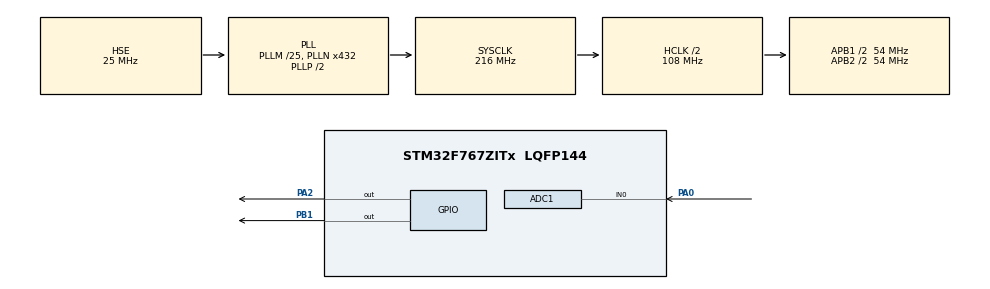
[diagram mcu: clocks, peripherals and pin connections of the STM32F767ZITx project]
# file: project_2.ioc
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ADC1.Channel-0\#ChannelRegularConversion=ADC_CHANNEL_0
ADC1.ClockPrescaler=ADC_CLOCK_SYNC_PCLK_DIV4
ADC1.ContinuousConvMode=ENABLE
ADC1.DMAContinuousRequests=ENABLE
ADC1.NbrOfConversion=1
ADC1.NbrOfConversionFlag=1
ADC1.Rank-0\#ChannelRegularConversion=1
ADC1.SamplingTime-0\#ChannelRegularConversion=ADC_SAMPLETIME_3CYCLES
ADC1.master=1
CORTEX_M7.default_mode_Activation=1
Dma.ADC1.0.Direction=DMA_PERIPH_TO_MEMORY
Dma.ADC1.0.FIFOMode=DMA_FIFOMODE_DISABLE
Dma.ADC1.0.Instance=DMA2_Stream0
Dma.ADC1.0.MemDataAlignment=DMA_MDATAALIGN_HALFWORD
Dma.ADC1.0.MemInc=DMA_MINC_ENABLE
Dma.ADC1.0.Mode=DMA_NORMAL
Dma.ADC1.0.PeriphDataAlignment=DMA_PDATAALIGN_HALFWORD
Dma.ADC1.0.PeriphInc=DMA_PINC_DISABLE
Dma.ADC1.0.Priority=DMA_PRIORITY_LOW
Dma.Request0=ADC1
Mcu.Family=STM32F7
Mcu.Name=STM32F767ZITx
Mcu.Package=LQFP144
NVIC.DMA2_Stream0_IRQn=true\:0\:0\:false\:false\:true\:false\:true\:true
NVIC.PriorityGroup=NVIC_PRIORITYGROUP_4
PA0/WKUP.Signal=ADCx_IN0
PA2.Signal=GPIO_Output
PB1.Signal=GPIO_Output
PD8.Signal=USART3_TX
PD9.Signal=USART3_RX
PH0/OSC_IN.Mode=HSE-External-Oscillator
PH0/OSC_IN.Signal=RCC_OSC_IN
PH1/OSC_OUT.Mode=HSE-External-Oscillator
PH1/OSC_OUT.Signal=RCC_OSC_OUT
ProjectManager.HeapSize=0x200
ProjectManager.StackSize=0x400
ProjectManager.TargetToolchain=STM32CubeIDE
RCC.AHBCLKDivider=RCC_SYSCLK_DIV2
RCC.AHBFreq_Value=108000000
RCC.APB1CLKDivider=RCC_HCLK_DIV2
RCC.APB1Freq_Value=54000000
RCC.APB1TimFreq_Value=108000000
RCC.APB2CLKDivider=RCC_HCLK_DIV2
RCC.APB2Freq_Value=54000000
RCC.APB2TimFreq_Value=108000000
RCC.CortexFreq_Value=108000000
RCC.HCLKFreq_Value=108000000
RCC.HSE_VALUE=25000000
RCC.HSI_VALUE=16000000
RCC.LSE_VALUE=32768
RCC.PLLM=25
RCC.PLLN=432
RCC.PLLSourceVirtual=RCC_PLLSOURCE_HSE
RCC.SYSCLKFreq_VALUE=216000000
RCC.SYSCLKSource=RCC_SYSCLKSOURCE_PLLCLK
RCC.USBFreq_Value=216000000
RCC.VCOOutputFreq_Value=432000000
SH.ADCx_IN0.0=ADC1_IN0,IN0
board=custom

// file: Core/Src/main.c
/* USER CODE BEGIN Header */
/**
  ******************************************************************************
  * @file           : main.c
  * @brief          : Main program body
  ******************************************************************************
  * @attention
  *
  * Copyright (c) 2026 STMicroelectronics.
  * All rights reserved.
  *
  * This software is licensed under terms that can be found in the LICENSE file
  * in the root directory of this software component.
  * If no LICENSE file comes with this software, it is provided AS-IS.
  *
  ******************************************************************************
  */
/* USER CODE END Header */
#include "main.h"
#include "adc.h"
#include "dma.h"
#include "gpio.h"

/* USER CODE BEGIN PD */
#define MAX_SAMPLES 1000
/* USER CODE END PD */

/* USER CODE BEGIN PV */
ALIGN_32BYTES(uint16_t adc_buffer[MAX_SAMPLES]);
volatile uint8_t adc_conv_complete = 0;
volatile uint32_t sampling_time_us = 0;
volatile uint16_t plot_val = 0; // ตัวแปรสำหรับส่งให้ SWV Trace
/* USER CODE END PV */

void SystemClock_Config(void);
static void MPU_Config(void);
/* USER CODE BEGIN PFP */
void Capture_ADC_DMA(void);
static inline uint32_t DWT_GetMicros(void);
/* USER CODE END PFP */

/* USER CODE BEGIN 0 */
static inline uint32_t DWT_GetMicros(void) {
    // ใช้ HAL_RCC_GetHCLKFreq() แทน SystemCoreClock เพื่อความแม่นยำ
    return DWT->CYCCNT / (HAL_RCC_GetHCLKFreq() / 1000000UL);
}

void HAL_ADC_ConvCpltCallback(ADC_HandleTypeDef* hadc) {
    if (hadc->Instance == ADC1) {
        adc_conv_complete = 1;
    }
}

void Capture_ADC_DMA(void) {
    adc_conv_complete = 0;

    uint32_t t_start = DWT_GetMicros();
    HAL_ADC_Start_DMA(&hadc1, (uint32_t*)adc_buffer, MAX_SAMPLES);

    // รอดูดข้อมูลจนครบ 1,000 จุด
    while (!adc_conv_complete);

    HAL_ADC_Stop_DMA(&hadc1);
    sampling_time_us = DWT_GetMicros() - t_start;

    // เคลียร์ D-Cache เพื่อให้ CPU อ่านค่าจริงจาก SRAM
    SCB_InvalidateDCache_by_Addr((uint32_t*)adc_buffer, sizeof(adc_buffer));
}
/* USER CODE END 0 */

int main(void)
{

  /* MPU Configuration--------------------------------------------------------*/
  MPU_Config();

  /* MCU Configuration--------------------------------------------------------*/

  /* Reset of all peripherals, Initializes the Flash interface and the Systick. */
  HAL_Init();

  /* Configure the system clock */
  SystemClock_Config();

  /* Initialize all configured peripherals */
  MX_GPIO_Init();
  MX_DMA_Init();
  MX_ADC1_Init();
  /* USER CODE BEGIN 2 */
  // เปิด Core Debug
  CoreDebug->DEMCR |= CoreDebug_DEMCR_TRCENA_Msk;

  // ปลดล็อก Software Lock ของ DWT บน Cortex-M7 (สำคัญมาก)
  *((volatile uint32_t *)0xE0001FB0) = 0xC5ACCE55;

  // รีเซ็ตตัวนับและเปิดการทำงานของ CYCCNT
  DWT->CYCCNT = 0;
  DWT->CTRL |= DWT_CTRL_CYCCNTENA_Msk;
  /* USER CODE END 2 */

  /* Infinite loop */
  /* USER CODE BEGIN WHILE */
  while (1)
  {
      Capture_ADC_DMA();
      for (int i = 0; i < MAX_SAMPLES; i++) {
              plot_val = adc_buffer[i];
          }
      HAL_Delay(10);
    /* USER CODE END WHILE */

  }
}

void SystemClock_Config(void)
{
  RCC_OscInitTypeDef RCC_OscInitStruct = {0};
  RCC_ClkInitTypeDef RCC_ClkInitStruct = {0};

  /** Configure the main internal regulator output voltage
  */
  __HAL_RCC_PWR_CLK_ENABLE();
  __HAL_PWR_VOLTAGESCALING_CONFIG(PWR_REGULATOR_VOLTAGE_SCALE3);

  /** Initializes the RCC Oscillators according to the specified parameters
  * in the RCC_OscInitTypeDef structure.
  */
  RCC_OscInitStruct.OscillatorType = RCC_OSCILLATORTYPE_HSE;
  RCC_OscInitStruct.HSEState = RCC_HSE_ON;
  RCC_OscInitStruct.PLL.PLLState = RCC_PLL_ON;
  RCC_OscInitStruct.PLL.PLLSource = RCC_PLLSOURCE_HSE;
  RCC_OscInitStruct.PLL.PLLM = 25;
  RCC_OscInitStruct.PLL.PLLN = 432;
  RCC_OscInitStruct.PLL.PLLP = RCC_PLLP_DIV2;
  RCC_OscInitStruct.PLL.PLLQ = 2;
  RCC_OscInitStruct.PLL.PLLR = 2;
  if (HAL_RCC_OscConfig(&RCC_OscInitStruct) != HAL_OK)
  {
    Error_Handler();
  }

  /** Activate the Over-Drive mode
  */
  if (HAL_PWREx_EnableOverDrive() != HAL_OK)
  {
    Error_Handler();
  }

  /** Initializes the CPU, AHB and APB buses clocks
  */
  RCC_ClkInitStruct.ClockType = RCC_CLOCKTYPE_HCLK|RCC_CLOCKTYPE_SYSCLK
                              |RCC_CLOCKTYPE_PCLK1|RCC_CLOCKTYPE_PCLK2;
  RCC_ClkInitStruct.SYSCLKSource = RCC_SYSCLKSOURCE_PLLCLK;
  RCC_ClkInitStruct.AHBCLKDivider = RCC_SYSCLK_DIV2;
  RCC_ClkInitStruct.APB1CLKDivider = RCC_HCLK_DIV2;
  RCC_ClkInitStruct.APB2CLKDivider = RCC_HCLK_DIV2;

  if (HAL_RCC_ClockConfig(&RCC_ClkInitStruct, FLASH_LATENCY_3) != HAL_OK)
  {
    Error_Handler();
  }
}

 /* MPU Configuration */

void MPU_Config(void)
{
  MPU_Region_InitTypeDef MPU_InitStruct = {0};

  /* Disables the MPU */
  HAL_MPU_Disable();

  /** Initializes and configures the Region and the memory to be protected
  */
  MPU_InitStruct.Enable = MPU_REGION_ENABLE;
  MPU_InitStruct.Number = MPU_REGION_NUMBER0;
  MPU_InitStruct.BaseAddress = 0x0;
  MPU_InitStruct.Size = MPU_REGION_SIZE_4GB;
  MPU_InitStruct.SubRegionDisable = 0x87;
  MPU_InitStruct.TypeExtField = MPU_TEX_LEVEL0;
  MPU_InitStruct.AccessPermission = MPU_REGION_NO_ACCESS;
  MPU_InitStruct.DisableExec = MPU_INSTRUCTION_ACCESS_DISABLE;
  MPU_InitStruct.IsShareable = MPU_ACCESS_SHAREABLE;
  MPU_InitStruct.IsCacheable = MPU_ACCESS_NOT_CACHEABLE;
  MPU_InitStruct.IsBufferable = MPU_ACCESS_NOT_BUFFERABLE;

  HAL_MPU_ConfigRegion(&MPU_InitStruct);
  /* Enables the MPU */
  HAL_MPU_Enable(MPU_PRIVILEGED_DEFAULT);

}

void Error_Handler(void)
{
  __disable_irq();
  while (1)
  {
  }
}
